# SC000 register map
Vendor: Arm Ltd.; Series: ARMv6-M; File version: 1.0.0
CPU: SC000 r0p0, little endian, MPU, no FPU, 2 interrupt priority bits
Registers are 32-bit, read-write, reset 0x0 unless marked. A register's access mark holds for its fields unless they carry their own. Offsets are from the block's base; [hi:lo] are bit positions; {n}, {i} and the like mark numbered series.

## SysTick — 24-bit system timer that counts down from LOAD to 0 on the processor or reference clock and can raise the SysTick exception; the usual RTOS tick source. Banked per security state on ARMv8-M with the Security Extension.
Base 0xE000E010
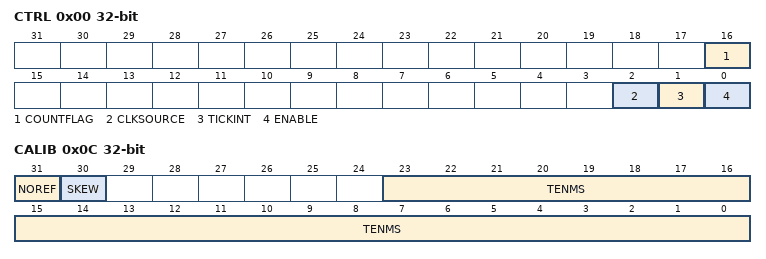
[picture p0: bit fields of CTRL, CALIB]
0x00 CTRL — SysTick Control and Status Register: enable, interrupt enable, clock source and the sticky count-to-zero flag.
  [16] COUNTFLAG ro — Reads 1 if the counter reached 0 since the last read of this register. Cleared by reading CTRL or writing VAL.
  [2] CLKSOURCE — Clock source: 0 = external reference clock (implementation defined, e.g. HCLK/8), 1 = processor clock.
    0=External reference clock (implementation defined); 1=Processor clock
  [1] TICKINT — 1 = counting down to 0 sets the SysTick exception pending; 0 = poll COUNTFLAG instead.
  [0] ENABLE — Counter enable: 1 = SysTick counts down from LOAD to 0 and reloads.
0x04 LOAD — SysTick Reload Value Register: value loaded into VAL when the counter reaches 0. A period of N clocks needs RELOAD = N-1.
  [23:0] RELOAD — Value loaded into VAL when the counter reaches 0. A period of N clocks needs RELOAD = N-1; 0 is legal but the counter then never fires.
0x08 VAL — SysTick Current Value Register: the current count. Any write clears it to 0 and clears CTRL.COUNTFLAG; the next reload comes from LOAD.
  [23:0] CURRENT — Current counter value. Any write clears the field to 0 and clears CTRL.COUNTFLAG.
0x0C CALIB ro — SysTick Calibration Register: implementation-defined reload value for a 10 ms tick and whether a reference clock exists.
  [31] NOREF — 1 = no separate reference clock: CLKSOURCE reads 1 and cannot be cleared.
  [30] SKEW — 1 = TENMS is not exact (a 10 ms tick cannot be produced exactly).
  [23:0] TENMS — Reload value for a 10 ms period with the reference clock, or 0 if unknown. Implementation defined.

## NVIC — Nested Vectored Interrupt Controller: enable, pending, active and priority registers for the external interrupts (IRQ0 = exception 16) and the software trigger register. Bit k of register n refers to IRQ 32n+k.
Base 0xE000E100
0x00 ISER0 — Interrupt Set-Enable Register n (IRQ 32n..32n+31): write 1 to enable an interrupt, 0 has no effect; reads the enable state.
  [31:0] SETENA — Bit k: write 1 to enable IRQ 32n+k; reads 1 if enabled. Writing 0 has no effect.
0x80 ICER0 — Interrupt Clear-Enable Register n (IRQ 32n..32n+31): write 1 to disable an interrupt, 0 has no effect; reads the enable state.
  [31:0] CLRENA — Bit k: write 1 to disable IRQ 32n+k; reads 1 if enabled. Writing 0 has no effect.
0x100 ISPR0 — Interrupt Set-Pending Register n (IRQ 32n..32n+31): write 1 to set an interrupt pending; reads the pending state.
  [31:0] SETPEND — Bit k: write 1 to set IRQ 32n+k pending; reads 1 if pending.
0x180 ICPR0 — Interrupt Clear-Pending Register n (IRQ 32n..32n+31): write 1 to clear a pending interrupt; reads the pending state.
  [31:0] CLRPEND — Bit k: write 1 to clear IRQ 32n+k pending; reads 1 if pending.
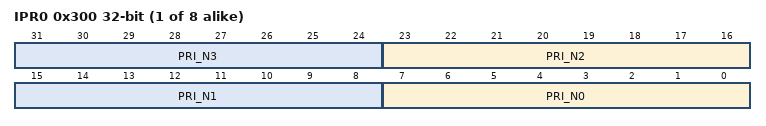
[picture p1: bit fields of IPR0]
{0x300+4i} IPR{i} (i=0..7) — Interrupt Priority Register n: one byte per interrupt, IRQ 4n+0 in bits [7:0] up to IRQ 4n+3 in [31:24]. Lower value = higher priority; only the top nvicPrioBits of each byte are implemented (ARMv6-M: 2, typical ARMv7-M: 3-4).
  [8n+7:8n] PRI_N{n} (n=0..3) — Priority of interrupt 4n+{n}. Only the top nvicPrioBits (implementation defined, 2 to 8) are implemented; the rest read as zero.

## MPU — Memory Protection Unit (optional): programmable regions with access permissions and memory attributes, checked on every access. ARMv6-M/v7-M (PMSAv7) use RBAR/RASR power-of-two regions; ARMv8-M (PMSAv8) uses RBAR/RLAR base-limit regions with MAIR attributes.
Base 0xE000ED90
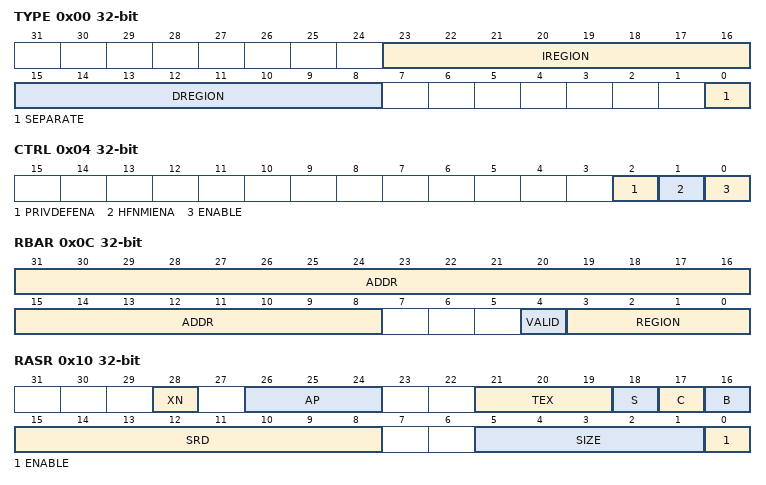
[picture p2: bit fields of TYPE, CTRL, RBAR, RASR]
0x00 TYPE ro — MPU Type Register: how many regions the MPU implements (0 = no MPU). Read-only.
  [23:16] IREGION — Number of instruction regions; always 0 (unified).
  [15:8] DREGION — Number of MPU regions implemented (0 = no MPU; Cortex-M cores offer 8 or 16).
  [0] SEPARATE — 0 = unified MPU (instruction and data share the regions). Always 0 on Cortex-M.
0x04 CTRL — MPU Control Register: global enable, behaviour during HardFault/NMI, and the privileged default memory map.
  [2] PRIVDEFENA — 1 = privileged accesses to addresses not covered by any enabled region use the default memory map; 0 = they raise a MemManage fault (unprivileged accesses always fault).
  [1] HFNMIENA — 1 = the MPU stays enabled during HardFault, NMI and FAULTMASK handlers; 0 = those handlers use the default memory map (the usual choice).
  [0] ENABLE — MPU enable. When 0 the default memory map applies to all accesses.
0x08 RNR — MPU Region Number Register: selects the region that RBAR and RASR/RLAR access.
  [7:0] REGION — Region number selected for RBAR/RASR (RLAR) accesses.
0x0C RBAR — MPU Region Base Address Register for the region selected by RNR (ARMv7-M: also selects the region when VALID is set). ARMv8-M: base address, shareability, access permissions and XN.
  [31:8] ADDR — Region base address. Must be aligned to the region size; the bits below the size (as set in RASR.SIZE) are ignored.
  [4] VALID wo — Write 1 to also write REGION into RNR in the same access, so base and number can be set with one store. Reads as 0.
  [3:0] REGION — Region number to select when VALID = 1; reads back the current RNR.
0x10 RASR — MPU Region Attribute and Size Register (ARMv7-M/v6-M PMSAv7): enable, power-of-two size, subregion disables and the memory attributes/permissions of the selected region.
  [28] XN — Execute never: 1 = instruction fetches from this region raise an IACCVIOL MemManage fault.
  [26:24] AP — Access permissions (privileged/unprivileged): 0 = no access, 1 = RW/no access, 2 = RW/RO, 3 = RW/RW, 5 = RO/no access, 6 or 7 = RO/RO.
    0=NoAccess; 1=PrivRW (Privileged read/write, unprivileged no access); 2=PrivRW_UserRO (Privileged read/write, unprivileged read-only); 3=FullAccess (Read/write for all); 5=PrivRO (Privileged read-only, unprivileged no access); 6=Read-only for all; 7=ReadOnly_7 (Read-only for all)
  [21:19] TEX — Type extension: 0 = standard types via C/B, 1 with C=B=0 Normal non-cacheable, 1 with C=B=1 write-back write-allocate, 2 = Device non-shareable, 4-7 = separate outer/inner cache policies in TEX[1:0] and C/B.
  [18] S — Shareable: 1 = the region is shared with other bus masters (DMA) - cacheable shared memory is treated as non-cacheable on Cortex-M7 unless CACR.SIWT is set.
  [17] C — Cacheable (see B).
  [16] B — Bufferable (with C and TEX selects the memory type: TEX=0 C=0 B=0 Strongly-ordered, B=1 Device; C=1 B=0 write-through, C=1 B=1 write-back).
  [15:8] SRD — Subregion disable: bit k = 1 disables the k-th eighth of the region (regions of 256 bytes or more). Lets a region punch holes in a larger one.
  [5:1] SIZE — Region size = 2^(SIZE+1) bytes: 4 = 32 B (minimum), 7 = 256 B, 11 = 4 KB, 19 = 1 MB, 31 = 4 GB.
  [0] ENABLE — Region enable.

## DCB — Debug Control Block: halting debug control and status (DHCSR), core register access from the debugger (DCRSR/DCRDR), vector catch, the DebugMonitor exception and trace enable (DEMCR), and on ARMv8-M debug authentication and security control.
Base 0xE000EDF0
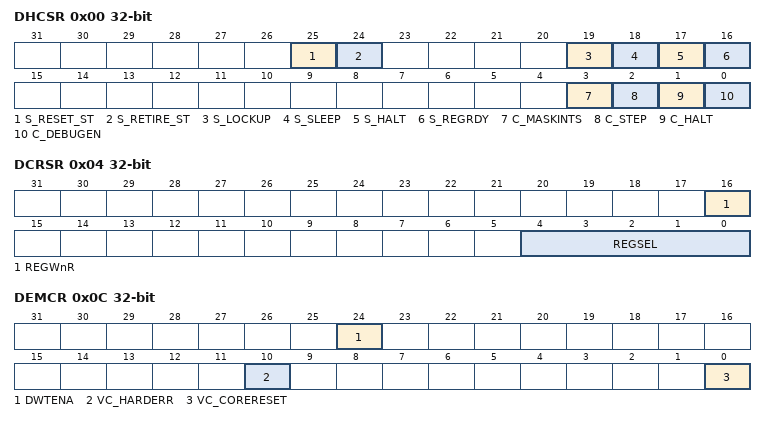
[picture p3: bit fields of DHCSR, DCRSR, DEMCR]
0x00 DHCSR — Debug Halting Control and Status Register: debugger enable, halt, step and interrupt masking (writes need 0xA05F in bits [31:16], DBGKEY), and read-only processor status (halted, sleeping, locked up, reset since last read) in the same upper bits.
  [25] S_RESET_ST ro — Sticky: the processor was reset since the last read of DHCSR. Cleared on read.
  [24] S_RETIRE_ST ro — Sticky: at least one instruction retired since the last read of DHCSR. Cleared on read.
  [19] S_LOCKUP ro — Processor is in lockup state - a fault occurred at priority -1 or in NMI/HardFault with no way to escalate; PC reads 0xFFFFFFFE. Read-only.
  [18] S_SLEEP ro — Processor is sleeping (WFI, WFE or sleep-on-exit). Read-only.
  [17] S_HALT ro — Processor is in Debug state (halted). Read-only.
  [16] S_REGRDY ro — Register transfer complete: a DCRSR read/write has finished and DCRDR is valid. Read-only.
  [3] C_MASKINTS — Mask PendSV, SysTick and IRQ (not NMI/faults) while stepping, so a step does not enter an interrupt handler. Change only while halted, together with C_HALT.
  [2] C_STEP — Single step: 1 = when leaving Debug state, execute one instruction and halt again.
  [1] C_HALT — Halt request: 1 = halt the processor (Debug state); 0 = run. Needs C_DEBUGEN = 1.
  [0] C_DEBUGEN — Halting debug enable. Set by the debugger; cannot be set by software. While 0 the other C_* bits are ignored and BKPT with no monitor escalates to HardFault.
0x04 DCRSR wo — Debug Core Register Selector Register: with the processor halted, selects a core register to transfer to or from DCRDR. Poll DHCSR.S_REGRDY for completion.
  [16] REGWnR — Direction: 0 = read the selected register into DCRDR, 1 = write DCRDR to the selected register.
  [4:0] REGSEL — Register to transfer: 0-12 R0-R12, 13 SP (current), 14 LR, 15 DebugReturnAddress (PC), 16 xPSR, 17 MSP, 18 PSP, 20 packed CONTROL[31:24] FAULTMASK[16] BASEPRI[8] PRIMASK[0], 33 FPSCR, 64-95 S0-S31; ARMv8-M: 24 MSP_NS, 25 PSP_NS, 26 MSP_S, 27 PSP_S, 28 MSPLIM_S, 29 PSPLIM_S, 30 MSPLIM_NS, 31 PSPLIM_NS, 34/35 packed CONTROL/masks _S/_NS.
0x08 DCRDR — Debug Core Register Data Register: data for DCRSR transfers. Also usable as a general debugger-to-target mailbox.
  [31:0] DBGTMP — Data read from, or to be written to, the register selected by DCRSR.
0x0C DEMCR — Debug Exception and Monitor Control Register: vector catch on reset and faults, DebugMonitor exception control, and TRCENA, the global enable for DWT, ITM, ETM and TPIU.
  [24] DWTENA — Enable the DWT (Data Watchpoint and Trace) unit. Must be set before programming DWT comparators.
  [10] VC_HARDERR — Vector catch on HardFault entry - with this set the core halts at the fault instead of running the HardFault handler.
  [0] VC_CORERESET — Vector catch on core reset: halt immediately after reset (the 'reset catch' debuggers use to stop at the first instruction). Needs C_DEBUGEN.
